AUTOSAR XML (schema 4-2-1)
standard types defined: uint8, uint8_DataConstr
package /ComponentTypes
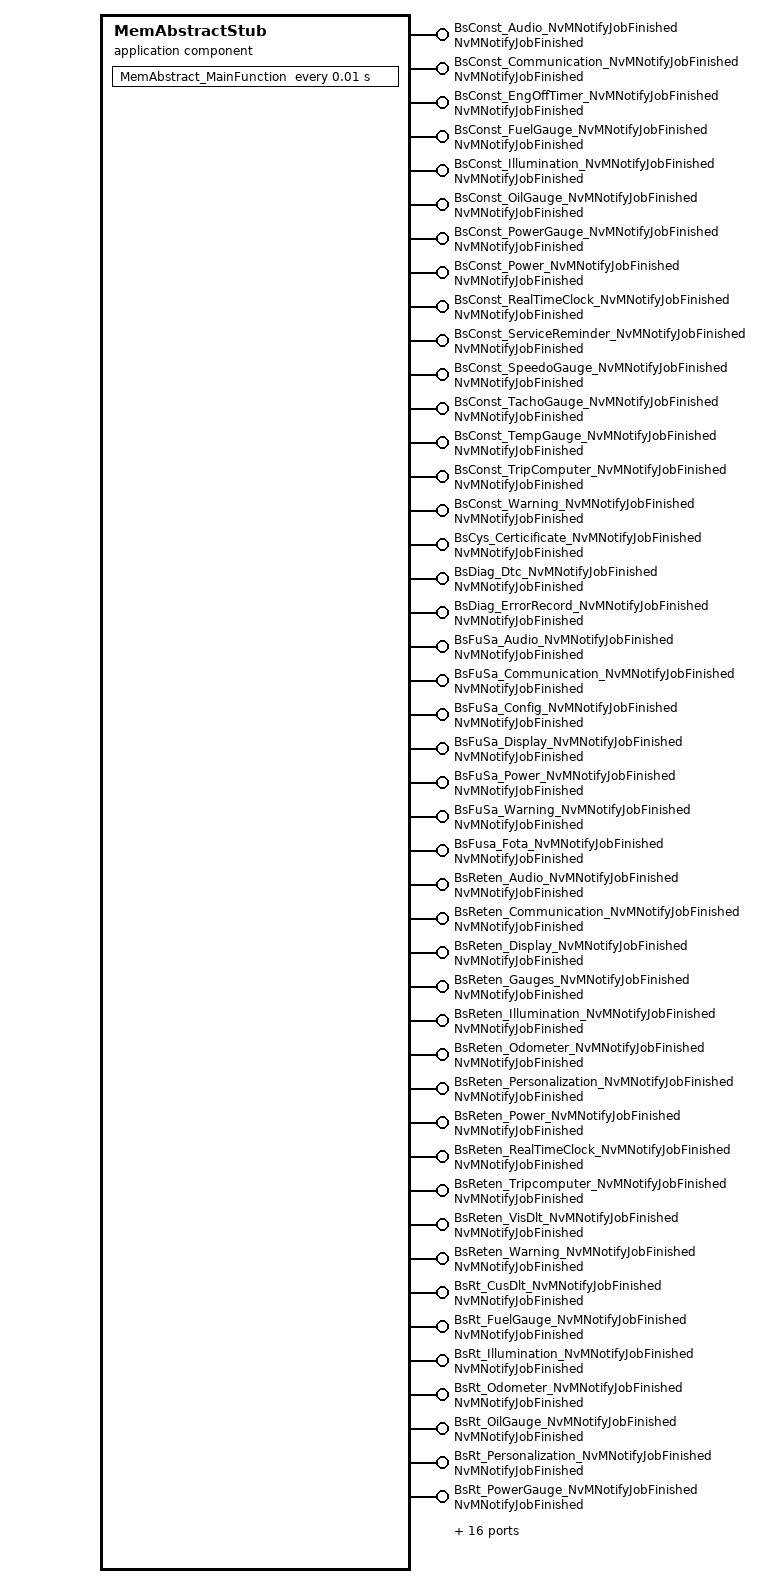
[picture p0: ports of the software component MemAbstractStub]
  application sw component type MemAbstractStub
    60 x provide port, all with server-com-spec{operation=JobFinished, queue-length=1}, provided-interface=NvMNotifyJobFinished:
      BsConst_Audio_NvMNotifyJobFinished
      BsConst_Communication_NvMNotifyJobFinished
      BsConst_EngOffTimer_NvMNotifyJobFinished
      BsConst_FuelGauge_NvMNotifyJobFinished
      BsConst_Illumination_NvMNotifyJobFinished
      BsConst_OilGauge_NvMNotifyJobFinished
      BsConst_PowerGauge_NvMNotifyJobFinished
      BsConst_Power_NvMNotifyJobFinished
      BsConst_RealTimeClock_NvMNotifyJobFinished
      BsConst_ServiceReminder_NvMNotifyJobFinished
      BsConst_SpeedoGauge_NvMNotifyJobFinished
      BsConst_TachoGauge_NvMNotifyJobFinished
      BsConst_TempGauge_NvMNotifyJobFinished
      BsConst_TripComputer_NvMNotifyJobFinished
      BsConst_Warning_NvMNotifyJobFinished
      BsCys_Certicificate_NvMNotifyJobFinished
      BsDiag_Dtc_NvMNotifyJobFinished
      BsDiag_ErrorRecord_NvMNotifyJobFinished
      BsFuSa_Audio_NvMNotifyJobFinished
      BsFuSa_Communication_NvMNotifyJobFinished
      BsFuSa_Config_NvMNotifyJobFinished
      BsFuSa_Display_NvMNotifyJobFinished
      BsFuSa_Power_NvMNotifyJobFinished
      BsFuSa_Warning_NvMNotifyJobFinished
      BsFusa_Fota_NvMNotifyJobFinished
      BsReten_Audio_NvMNotifyJobFinished
      BsReten_Communication_NvMNotifyJobFinished
      BsReten_Display_NvMNotifyJobFinished
      BsReten_Gauges_NvMNotifyJobFinished
      BsReten_Illumination_NvMNotifyJobFinished
      BsReten_Odometer_NvMNotifyJobFinished
      BsReten_Personalization_NvMNotifyJobFinished
      BsReten_Power_NvMNotifyJobFinished
      BsReten_RealTimeClock_NvMNotifyJobFinished
      BsReten_Tripcomputer_NvMNotifyJobFinished
      BsReten_VisDlt_NvMNotifyJobFinished
      BsReten_Warning_NvMNotifyJobFinished
      BsRt_CusDlt_NvMNotifyJobFinished
      BsRt_FuelGauge_NvMNotifyJobFinished
      BsRt_Illumination_NvMNotifyJobFinished
      BsRt_Odometer_NvMNotifyJobFinished
      BsRt_OilGauge_NvMNotifyJobFinished
      BsRt_Personalization_NvMNotifyJobFinished
      BsRt_PowerGauge_NvMNotifyJobFinished
      BsRt_RealTimeClock_NvMNotifyJobFinished
      BsRt_SpeedoGauge_NvMNotifyJobFinished
      BsRt_TachoGauge_NvMNotifyJobFinished
      BsRt_TempGauge_NvMNotifyJobFinished
      BsRt_TripComputer_NvMNotifyJobFinished
      BsRt_Warning_NvMNotifyJobFinished
      BsShare_EcuPartNumber_NvMNotifyJobFinished
      BsShare_SwUpdFotaFinPrint_NvMNotifyJobFinished
      BsShare_SwUpdFotaMode_NvMNotifyJobFinished
      BsShare_SwUpdFotaStatus_NvMNotifyJobFinished
      BsShare_SwUpdFotadecrypt_NvMNotifyJobFinished
      BsShare_SwUpdReflash_NvMNotifyJobFinished
      BsShare_VehicleConfig_NvMNotifyJobFinished
      BsShare_VisMeet_NvMNotifyJobFinished
      RefCys_Certicificate1_NvMNotifyJobFinished
      RefCys_Certicificate_NvMNotifyJobFinished
    behavior MemAbstractStub_InternalBehavior
      60 x operation invoked event:
        OIT_MemAbstractMdl_NotifyJobEnd_BsConst_Audio_NvMNotifyJobFinished_JobFinished: start-on-event=MemAbstractMdl_NotifyJobEnd_BsConst_Audio, operation=BsConst_Audio_NvMNotifyJobFinished.JobFinished
        OIT_MemAbstractMdl_NotifyJobEnd_BsConst_Communication_NvMNotifyJobFinished_JobFinished: start-on-event=MemAbstractMdl_NotifyJobEnd_BsConst_Communication, operation=BsConst_Communication_NvMNotifyJobFinished.JobFinished
        OIT_MemAbstractMdl_NotifyJobEnd_BsConst_EngOffTimer_NvMNotifyJobFinished_JobFinished: start-on-event=MemAbstractMdl_NotifyJobEnd_BsConst_EngOffTimer, operation=BsConst_EngOffTimer_NvMNotifyJobFinished.JobFinished
        OIT_MemAbstractMdl_NotifyJobEnd_BsConst_FuelGauge_NvMNotifyJobFinished_JobFinished: start-on-event=MemAbstractMdl_NotifyJobEnd_BsConst_FuelGauge, operation=BsConst_FuelGauge_NvMNotifyJobFinished.JobFinished
        OIT_MemAbstractMdl_NotifyJobEnd_BsConst_Illumination_NvMNotifyJobFinished_JobFinished: start-on-event=MemAbstractMdl_NotifyJobEnd_BsConst_Illumination, operation=BsConst_Illumination_NvMNotifyJobFinished.JobFinished
        OIT_MemAbstractMdl_NotifyJobEnd_BsConst_OilGauge_NvMNotifyJobFinished_JobFinished: start-on-event=MemAbstractMdl_NotifyJobEnd_BsConst_OilGauge, operation=BsConst_OilGauge_NvMNotifyJobFinished.JobFinished
        OIT_MemAbstractMdl_NotifyJobEnd_BsConst_PowerGauge_NvMNotifyJobFinished_JobFinished: start-on-event=MemAbstractMdl_NotifyJobEnd_BsConst_PowerGauge, operation=BsConst_PowerGauge_NvMNotifyJobFinished.JobFinished
        OIT_MemAbstractMdl_NotifyJobEnd_BsConst_Power_NvMNotifyJobFinished_JobFinished: start-on-event=MemAbstractMdl_NotifyJobEnd_BsConst_Power, operation=BsConst_Power_NvMNotifyJobFinished.JobFinished
        OIT_MemAbstractMdl_NotifyJobEnd_BsConst_RealTimeClock_NvMNotifyJobFinished_JobFinished: start-on-event=MemAbstractMdl_NotifyJobEnd_BsConst_RealTimeClock, operation=BsConst_RealTimeClock_NvMNotifyJobFinished.JobFinished
        OIT_MemAbstractMdl_NotifyJobEnd_BsConst_ServiceReminder_NvMNotifyJobFinished_JobFinished: start-on-event=MemAbstractMdl_NotifyJobEnd_BsConst_ServiceReminder, operation=BsConst_ServiceReminder_NvMNotifyJobFinished.JobFinished
        OIT_MemAbstractMdl_NotifyJobEnd_BsConst_SpeedoGauge_NvMNotifyJobFinished_JobFinished: start-on-event=MemAbstractMdl_NotifyJobEnd_BsConst_SpeedoGauge, operation=BsConst_SpeedoGauge_NvMNotifyJobFinished.JobFinished
        OIT_MemAbstractMdl_NotifyJobEnd_BsConst_TachoGauge_NvMNotifyJobFinished_JobFinished: start-on-event=MemAbstractMdl_NotifyJobEnd_BsConst_TachoGauge, operation=BsConst_TachoGauge_NvMNotifyJobFinished.JobFinished
        OIT_MemAbstractMdl_NotifyJobEnd_BsConst_TempGauge_NvMNotifyJobFinished_JobFinished: start-on-event=MemAbstractMdl_NotifyJobEnd_BsConst_TempGauge, operation=BsConst_TempGauge_NvMNotifyJobFinished.JobFinished
        OIT_MemAbstractMdl_NotifyJobEnd_BsConst_TripComputer_NvMNotifyJobFinished_JobFinished: start-on-event=MemAbstractMdl_NotifyJobEnd_BsConst_TripComputer, operation=BsConst_TripComputer_NvMNotifyJobFinished.JobFinished
        OIT_MemAbstractMdl_NotifyJobEnd_BsConst_Warning_NvMNotifyJobFinished_JobFinished: start-on-event=MemAbstractMdl_NotifyJobEnd_BsConst_Warning, operation=BsConst_Warning_NvMNotifyJobFinished.JobFinished
        OIT_MemAbstractMdl_NotifyJobEnd_BsCys_Certicificate_NvMNotifyJobFinished_JobFinished: start-on-event=MemAbstractMdl_NotifyJobEnd_BsCys_Certicificate, operation=BsCys_Certicificate_NvMNotifyJobFinished.JobFinished
        OIT_MemAbstractMdl_NotifyJobEnd_BsDiag_Dtc_NvMNotifyJobFinished_JobFinished: start-on-event=MemAbstractMdl_NotifyJobEnd_BsDiag_Dtc, operation=BsDiag_Dtc_NvMNotifyJobFinished.JobFinished
        OIT_MemAbstractMdl_NotifyJobEnd_BsDiag_ErrorRecord_NvMNotifyJobFinished_JobFinished: start-on-event=MemAbstractMdl_NotifyJobEnd_BsDiag_ErrorRecord, operation=BsDiag_ErrorRecord_NvMNotifyJobFinished.JobFinished
        OIT_MemAbstractMdl_NotifyJobEnd_BsFuSa_Audio_NvMNotifyJobFinished_JobFinished: start-on-event=MemAbstractMdl_NotifyJobEnd_BsFuSa_Audio, operation=BsFuSa_Audio_NvMNotifyJobFinished.JobFinished
        OIT_MemAbstractMdl_NotifyJobEnd_BsFuSa_Communication_NvMNotifyJobFinished_JobFinished: start-on-event=MemAbstractMdl_NotifyJobEnd_BsFuSa_Communication, operation=BsFuSa_Communication_NvMNotifyJobFinished.JobFinished
        OIT_MemAbstractMdl_NotifyJobEnd_BsFuSa_Config_NvMNotifyJobFinished_JobFinished: start-on-event=MemAbstractMdl_NotifyJobEnd_BsFuSa_Config, operation=BsFuSa_Config_NvMNotifyJobFinished.JobFinished
        OIT_MemAbstractMdl_NotifyJobEnd_BsFuSa_Display_NvMNotifyJobFinished_JobFinished: start-on-event=MemAbstractMdl_NotifyJobEnd_BsFuSa_Display, operation=BsFuSa_Display_NvMNotifyJobFinished.JobFinished
        OIT_MemAbstractMdl_NotifyJobEnd_BsFuSa_Power_NvMNotifyJobFinished_JobFinished: start-on-event=MemAbstractMdl_NotifyJobEnd_BsFuSa_Power, operation=BsFuSa_Power_NvMNotifyJobFinished.JobFinished
        OIT_MemAbstractMdl_NotifyJobEnd_BsFuSa_Warning_NvMNotifyJobFinished_JobFinished: start-on-event=MemAbstractMdl_NotifyJobEnd_BsFuSa_Warning, operation=BsFuSa_Warning_NvMNotifyJobFinished.JobFinished
        OIT_MemAbstractMdl_NotifyJobEnd_BsFusa_Fota_NvMNotifyJobFinished_JobFinished: start-on-event=MemAbstractMdl_NotifyJobEnd_BsFusa_Fota, operation=BsFusa_Fota_NvMNotifyJobFinished.JobFinished
        OIT_MemAbstractMdl_NotifyJobEnd_BsReten_Audio_NvMNotifyJobFinished_JobFinished: start-on-event=MemAbstractMdl_NotifyJobEnd_BsReten_Audio, operation=BsReten_Audio_NvMNotifyJobFinished.JobFinished
        OIT_MemAbstractMdl_NotifyJobEnd_BsReten_Communication_NvMNotifyJobFinished_JobFinished: start-on-event=MemAbstractMdl_NotifyJobEnd_BsReten_Communication, operation=BsReten_Communication_NvMNotifyJobFinished.JobFinished
        OIT_MemAbstractMdl_NotifyJobEnd_BsReten_Display_NvMNotifyJobFinished_JobFinished: start-on-event=MemAbstractMdl_NotifyJobEnd_BsReten_Display, operation=BsReten_Display_NvMNotifyJobFinished.JobFinished
        OIT_MemAbstractMdl_NotifyJobEnd_BsReten_Gauges_NvMNotifyJobFinished_JobFinished: start-on-event=MemAbstractMdl_NotifyJobEnd_BsReten_Gauges, operation=BsReten_Gauges_NvMNotifyJobFinished.JobFinished
        OIT_MemAbstractMdl_NotifyJobEnd_BsReten_Illumination_NvMNotifyJobFinished_JobFinished: start-on-event=MemAbstractMdl_NotifyJobEnd_BsReten_Illumination, operation=BsReten_Illumination_NvMNotifyJobFinished.JobFinished
        OIT_MemAbstractMdl_NotifyJobEnd_BsReten_Odometer_NvMNotifyJobFinished_JobFinished: start-on-event=MemAbstractMdl_NotifyJobEnd_BsReten_Odometer, operation=BsReten_Odometer_NvMNotifyJobFinished.JobFinished
        OIT_MemAbstractMdl_NotifyJobEnd_BsReten_Personalization_NvMNotifyJobFinished_JobFinished: start-on-event=MemAbstractMdl_NotifyJobEnd_BsReten_Personalization, operation=BsReten_Personalization_NvMNotifyJobFinished.JobFinished
        OIT_MemAbstractMdl_NotifyJobEnd_BsReten_Power_NvMNotifyJobFinished_JobFinished: start-on-event=MemAbstractMdl_NotifyJobEnd_BsReten_Power, operation=BsReten_Power_NvMNotifyJobFinished.JobFinished
        OIT_MemAbstractMdl_NotifyJobEnd_BsReten_RealTimeClock_NvMNotifyJobFinished_JobFinished: start-on-event=MemAbstractMdl_NotifyJobEnd_BsReten_RealTimeClock, operation=BsReten_RealTimeClock_NvMNotifyJobFinished.JobFinished
        OIT_MemAbstractMdl_NotifyJobEnd_BsReten_Tripcomputer_NvMNotifyJobFinished_JobFinished: start-on-event=MemAbstractMdl_NotifyJobEnd_BsReten_Tripcomputer, operation=BsReten_Tripcomputer_NvMNotifyJobFinished.JobFinished
        OIT_MemAbstractMdl_NotifyJobEnd_BsReten_VisDlt_NvMNotifyJobFinished_JobFinished: start-on-event=MemAbstractMdl_NotifyJobEnd_BsReten_VisDlt, operation=BsReten_VisDlt_NvMNotifyJobFinished.JobFinished
        OIT_MemAbstractMdl_NotifyJobEnd_BsReten_Warning_NvMNotifyJobFinished_JobFinished: start-on-event=MemAbstractMdl_NotifyJobEnd_BsReten_Warning, operation=BsReten_Warning_NvMNotifyJobFinished.JobFinished
        OIT_MemAbstractMdl_NotifyJobEnd_BsRt_CusDlt_NvMNotifyJobFinished_JobFinished: start-on-event=MemAbstractMdl_NotifyJobEnd_BsRt_CusDlt, operation=BsRt_CusDlt_NvMNotifyJobFinished.JobFinished
        OIT_MemAbstractMdl_NotifyJobEnd_BsRt_FuelGauge_NvMNotifyJobFinished_JobFinished: start-on-event=MemAbstractMdl_NotifyJobEnd_BsRt_FuelGauge, operation=BsRt_FuelGauge_NvMNotifyJobFinished.JobFinished
        OIT_MemAbstractMdl_NotifyJobEnd_BsRt_Illumination_NvMNotifyJobFinished_JobFinished: start-on-event=MemAbstractMdl_NotifyJobEnd_BsRt_Illumination, operation=BsRt_Illumination_NvMNotifyJobFinished.JobFinished
        OIT_MemAbstractMdl_NotifyJobEnd_BsRt_Odometer_NvMNotifyJobFinished_JobFinished: start-on-event=MemAbstractMdl_NotifyJobEnd_BsRt_Odometer, operation=BsRt_Odometer_NvMNotifyJobFinished.JobFinished
        OIT_MemAbstractMdl_NotifyJobEnd_BsRt_OilGauge_NvMNotifyJobFinished_JobFinished: start-on-event=MemAbstractMdl_NotifyJobEnd_BsRt_OilGauge, operation=BsRt_OilGauge_NvMNotifyJobFinished.JobFinished
        OIT_MemAbstractMdl_NotifyJobEnd_BsRt_Personalization_NvMNotifyJobFinished_JobFinished: start-on-event=MemAbstractMdl_NotifyJobEnd_BsRt_Personalization, operation=BsRt_Personalization_NvMNotifyJobFinished.JobFinished
        OIT_MemAbstractMdl_NotifyJobEnd_BsRt_PowerGauge_NvMNotifyJobFinished_JobFinished: start-on-event=MemAbstractMdl_NotifyJobEnd_BsRt_PowerGauge, operation=BsRt_PowerGauge_NvMNotifyJobFinished.JobFinished
        OIT_MemAbstractMdl_NotifyJobEnd_BsRt_RealTimeClock_NvMNotifyJobFinished_JobFinished: start-on-event=MemAbstractMdl_NotifyJobEnd_BsRt_RealTimeClock, operation=BsRt_RealTimeClock_NvMNotifyJobFinished.JobFinished
        OIT_MemAbstractMdl_NotifyJobEnd_BsRt_SpeedoGauge_NvMNotifyJobFinished_JobFinished: start-on-event=MemAbstractMdl_NotifyJobEnd_BsRt_SpeedoGauge, operation=BsRt_SpeedoGauge_NvMNotifyJobFinished.JobFinished
        OIT_MemAbstractMdl_NotifyJobEnd_BsRt_TachoGauge_NvMNotifyJobFinished_JobFinished: start-on-event=MemAbstractMdl_NotifyJobEnd_BsRt_TachoGauge, operation=BsRt_TachoGauge_NvMNotifyJobFinished.JobFinished
        OIT_MemAbstractMdl_NotifyJobEnd_BsRt_TempGauge_NvMNotifyJobFinished_JobFinished: start-on-event=MemAbstractMdl_NotifyJobEnd_BsRt_TempGauge, operation=BsRt_TempGauge_NvMNotifyJobFinished.JobFinished
        OIT_MemAbstractMdl_NotifyJobEnd_BsRt_TripComputer_NvMNotifyJobFinished_JobFinished: start-on-event=MemAbstractMdl_NotifyJobEnd_BsRt_TripComputer, operation=BsRt_TripComputer_NvMNotifyJobFinished.JobFinished
        OIT_MemAbstractMdl_NotifyJobEnd_BsRt_Warning_NvMNotifyJobFinished_JobFinished: start-on-event=MemAbstractMdl_NotifyJobEnd_BsRt_Warning, operation=BsRt_Warning_NvMNotifyJobFinished.JobFinished
        OIT_MemAbstractMdl_NotifyJobEnd_BsShare_EcuPartNumber_NvMNotifyJobFinished_JobFinished: start-on-event=MemAbstractMdl_NotifyJobEnd_BsShare_EcuPartNumber, operation=BsShare_EcuPartNumber_NvMNotifyJobFinished.JobFinished
        OIT_MemAbstractMdl_NotifyJobEnd_BsShare_SwUpdFotaFinPrint_NvMNotifyJobFinished_JobFinished: start-on-event=MemAbstractMdl_NotifyJobEnd_BsShare_SwUpdFotaFinPrint, operation=BsShare_SwUpdFotaFinPrint_NvMNotifyJobFinished.JobFinished
        OIT_MemAbstractMdl_NotifyJobEnd_BsShare_SwUpdFotaMode_NvMNotifyJobFinished_JobFinished: start-on-event=MemAbstractMdl_NotifyJobEnd_BsShare_SwUpdFotaMode, operation=BsShare_SwUpdFotaMode_NvMNotifyJobFinished.JobFinished
        OIT_MemAbstractMdl_NotifyJobEnd_BsShare_SwUpdFotaStatus_NvMNotifyJobFinished_JobFinished: start-on-event=MemAbstractMdl_NotifyJobEnd_BsShare_SwUpdFotaStatus, operation=BsShare_SwUpdFotaStatus_NvMNotifyJobFinished.JobFinished
        OIT_MemAbstractMdl_NotifyJobEnd_BsShare_SwUpdFotadecrypt_NvMNotifyJobFinished_JobFinished: start-on-event=MemAbstractMdl_NotifyJobEnd_BsShare_SwUpdFotadecrypt, operation=BsShare_SwUpdFotadecrypt_NvMNotifyJobFinished.JobFinished
        OIT_MemAbstractMdl_NotifyJobEnd_BsShare_SwUpdReflash_NvMNotifyJobFinished_JobFinished: start-on-event=MemAbstractMdl_NotifyJobEnd_BsShare_SwUpdReflash, operation=BsShare_SwUpdReflash_NvMNotifyJobFinished.JobFinished
        OIT_MemAbstractMdl_NotifyJobEnd_BsShare_VehicleConfig_NvMNotifyJobFinished_JobFinished: start-on-event=MemAbstractMdl_NotifyJobEnd_BsShare_VehicleConfig, operation=BsShare_VehicleConfig_NvMNotifyJobFinished.JobFinished
        OIT_MemAbstractMdl_NotifyJobEnd_BsShare_VisMeet_NvMNotifyJobFinished_JobFinished: start-on-event=MemAbstractMdl_NotifyJobEnd_BsShare_VisMeet, operation=BsShare_VisMeet_NvMNotifyJobFinished.JobFinished
        OIT_MemAbstractMdl_NotifyJobEnd_RefCys_Certicificate1_NvMNotifyJobFinished_JobFinished: start-on-event=MemAbstractMdl_NotifyJobEnd_RefCys_Certicificate1, operation=RefCys_Certicificate1_NvMNotifyJobFinished.JobFinished
        OIT_MemAbstractMdl_NotifyJobEnd_RefCys_Certicificate_NvMNotifyJobFinished_JobFinished: start-on-event=MemAbstractMdl_NotifyJobEnd_RefCys_Certicificate, operation=RefCys_Certicificate_NvMNotifyJobFinished.JobFinished
      timing event TMT_MemAbstract_MainFunction: start-on-event=MemAbstract_MainFunction, period=0.01
      61 x runnable:
        MemAbstractMdl_NotifyJobEnd_BsConst_Audio
        MemAbstractMdl_NotifyJobEnd_BsConst_Communication
        MemAbstractMdl_NotifyJobEnd_BsConst_EngOffTimer
        MemAbstractMdl_NotifyJobEnd_BsConst_FuelGauge
        MemAbstractMdl_NotifyJobEnd_BsConst_Illumination
        MemAbstractMdl_NotifyJobEnd_BsConst_OilGauge
        MemAbstractMdl_NotifyJobEnd_BsConst_Power
        MemAbstractMdl_NotifyJobEnd_BsConst_PowerGauge
        MemAbstractMdl_NotifyJobEnd_BsConst_RealTimeClock
        MemAbstractMdl_NotifyJobEnd_BsConst_ServiceReminder
        MemAbstractMdl_NotifyJobEnd_BsConst_SpeedoGauge
        MemAbstractMdl_NotifyJobEnd_BsConst_TachoGauge
        MemAbstractMdl_NotifyJobEnd_BsConst_TempGauge
        MemAbstractMdl_NotifyJobEnd_BsConst_TripComputer
        MemAbstractMdl_NotifyJobEnd_BsConst_Warning
        MemAbstractMdl_NotifyJobEnd_BsCys_Certicificate
        MemAbstractMdl_NotifyJobEnd_BsDiag_Dtc
        MemAbstractMdl_NotifyJobEnd_BsDiag_ErrorRecord
        MemAbstractMdl_NotifyJobEnd_BsFuSa_Audio
        MemAbstractMdl_NotifyJobEnd_BsFuSa_Communication
        MemAbstractMdl_NotifyJobEnd_BsFuSa_Config
        MemAbstractMdl_NotifyJobEnd_BsFuSa_Display
        MemAbstractMdl_NotifyJobEnd_BsFuSa_Power
        MemAbstractMdl_NotifyJobEnd_BsFuSa_Warning
        MemAbstractMdl_NotifyJobEnd_BsFusa_Fota
        MemAbstractMdl_NotifyJobEnd_BsReten_Audio
        MemAbstractMdl_NotifyJobEnd_BsReten_Communication
        MemAbstractMdl_NotifyJobEnd_BsReten_Display
        MemAbstractMdl_NotifyJobEnd_BsReten_Gauges
        MemAbstractMdl_NotifyJobEnd_BsReten_Illumination
        MemAbstractMdl_NotifyJobEnd_BsReten_Odometer
        MemAbstractMdl_NotifyJobEnd_BsReten_Personalization
        MemAbstractMdl_NotifyJobEnd_BsReten_Power
        MemAbstractMdl_NotifyJobEnd_BsReten_RealTimeClock
        MemAbstractMdl_NotifyJobEnd_BsReten_Tripcomputer
        MemAbstractMdl_NotifyJobEnd_BsReten_VisDlt
        MemAbstractMdl_NotifyJobEnd_BsReten_Warning
        MemAbstractMdl_NotifyJobEnd_BsRt_CusDlt
        MemAbstractMdl_NotifyJobEnd_BsRt_FuelGauge
        MemAbstractMdl_NotifyJobEnd_BsRt_Illumination
        MemAbstractMdl_NotifyJobEnd_BsRt_Odometer
        MemAbstractMdl_NotifyJobEnd_BsRt_OilGauge
        MemAbstractMdl_NotifyJobEnd_BsRt_Personalization
        MemAbstractMdl_NotifyJobEnd_BsRt_PowerGauge
        MemAbstractMdl_NotifyJobEnd_BsRt_RealTimeClock
        MemAbstractMdl_NotifyJobEnd_BsRt_SpeedoGauge
        MemAbstractMdl_NotifyJobEnd_BsRt_TachoGauge
        MemAbstractMdl_NotifyJobEnd_BsRt_TempGauge
        MemAbstractMdl_NotifyJobEnd_BsRt_TripComputer
        MemAbstractMdl_NotifyJobEnd_BsRt_Warning
        MemAbstractMdl_NotifyJobEnd_BsShare_EcuPartNumber
        MemAbstractMdl_NotifyJobEnd_BsShare_SwUpdFotaFinPrint
        MemAbstractMdl_NotifyJobEnd_BsShare_SwUpdFotaMode
        MemAbstractMdl_NotifyJobEnd_BsShare_SwUpdFotaStatus
        MemAbstractMdl_NotifyJobEnd_BsShare_SwUpdFotadecrypt
        MemAbstractMdl_NotifyJobEnd_BsShare_SwUpdReflash
        MemAbstractMdl_NotifyJobEnd_BsShare_VehicleConfig
        MemAbstractMdl_NotifyJobEnd_BsShare_VisMeet
        MemAbstractMdl_NotifyJobEnd_RefCys_Certicificate
        MemAbstractMdl_NotifyJobEnd_RefCys_Certicificate1
        MemAbstract_MainFunction
  swc implementation MemAbstractStub_Implementation: behavior=MemAbstractStub_InternalBehavior
    code-descriptors:
      code Default: artifact-descriptors=autosar-engineering-object={short-label=Default, category=SWSRC}
package /Predefined_DEV/ImplementationDataTypes
  impl type NvM_RequestResultType: compu {0=NVM_REQ_OK, 1=NVM_REQ_NOT_OK, 2=NVM_REQ_PENDING, 3=NVM_REQ_INTEGRITY_FAILED, 4=NVM_REQ_BLOCK_SKIPPED, 5=NVM_REQ_NV_INVALIDATED, 6=NVM_REQ_CANCELED, 7=NVM_REQ_REDUNDANCY_FAILED, 8=NVM_REQ_RESTORED_FROM_ROM}, implementation-data-type=uint8
  impl type NvM_ServiceIdType: compu {6=NVM_READ_BLOCK, 7=NVM_WRITE_BLOCK, 8=NVM_RESTORE_BLOCK_DEFAULTS, 9=NVM_ERASE_BLOCK, 11=NVM_INVALIDATE_NV_BLOCK, 12=NVM_READ_ALL}, implementation-data-type=uint8
package /Predefined_DEV/PortInterfaces
  client server interface NvMNotifyJobFinished: is-service=true
    operation JobFinished
      arg ServiceId: type=NvM_ServiceIdType, direction=IN, server-argument-impl-policy=USE-ARGUMENT-TYPE
      arg JobResult: type=NvM_RequestResultType, direction=IN, server-argument-impl-policy=USE-ARGUMENT-TYPE
